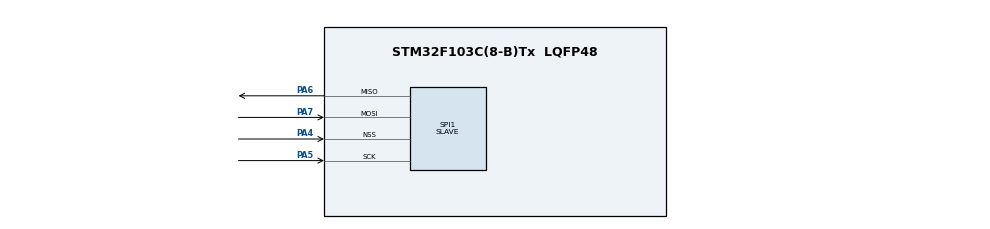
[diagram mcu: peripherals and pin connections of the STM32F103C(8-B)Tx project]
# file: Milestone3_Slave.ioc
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Mcu.Family=STM32F1
Mcu.Name=STM32F103C(8-B)Tx
Mcu.Package=LQFP48
NVIC.PriorityGroup=NVIC_PRIORITYGROUP_4
PA4.Mode=NSS_Signal_Hard_Input
PA4.Signal=SPI1_NSS
PA5.Mode=Full_Duplex_Slave
PA5.Signal=SPI1_SCK
PA6.Mode=Full_Duplex_Slave
PA6.Signal=SPI1_MISO
PA7.Mode=Full_Duplex_Slave
PA7.Signal=SPI1_MOSI
ProjectManager.HeapSize=0x200
ProjectManager.StackSize=0x400
ProjectManager.TargetToolchain=STM32CubeIDE
RCC.APB1Freq_Value=8000000
RCC.APB2Freq_Value=8000000
SPI1.Direction=SPI_DIRECTION_2LINES
SPI1.Mode=SPI_MODE_SLAVE
SPI1.VirtualNSS=VM_NSSHARD
SPI1.VirtualType=VM_SLAVE
VP_SYS_VS_ND.Mode=No_Debug
board=custom

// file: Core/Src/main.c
/* USER CODE BEGIN Header */
/**
  ******************************************************************************
  * @file           : main.c
  * @brief          : Main program body
  ******************************************************************************
  * @attention
  *
  * Copyright (c) 2026 STMicroelectronics.
  * All rights reserved.
  *
  * This software is licensed under terms that can be found in the LICENSE file
  * in the root directory of this software component.
  * If no LICENSE file comes with this software, it is provided AS-IS.
  *
  ******************************************************************************
  */
/* USER CODE END Header */
#include "main.h"

/* USER CODE BEGIN PTD */
typedef struct
{
    uint16_t id;
    uint8_t voltage_x10;
    uint16_t speed;
} CaseData;
/* USER CODE END PTD */

SPI_HandleTypeDef hspi1;

/* USER CODE BEGIN PV */
CaseData cases[5] =
{
    {0x1001, 123, 200},
    {0x1002, 142, 150},
    {0x1003, 138, 100},
    {0x1004, 115, 220},
    {0x1005, 109, 280}
};

uint8_t id_rx[2];
uint8_t tx_data[3];
/* USER CODE END PV */

void SystemClock_Config(void);
static void MX_GPIO_Init(void);
static void MX_SPI1_Init(void);

int main(void)
{

  /* MCU Configuration--------------------------------------------------------*/

  /* Reset of all peripherals, Initializes the Flash interface and the Systick. */
  HAL_Init();

  /* Configure the system clock */
  SystemClock_Config();

  /* Initialize all configured peripherals */
  MX_GPIO_Init();
  MX_SPI1_Init();

  /* Infinite loop */
  while (1)
  {
	    HAL_SPI_Receive(&hspi1,
	                    id_rx,
	                    2,
	                    HAL_MAX_DELAY);

	    uint16_t received_id =
	        ((uint16_t)id_rx[0] << 8) | id_rx[1];

	    for (int i = 0; i < 5; i++)
	    {
	        if (cases[i].id == received_id)
	        {
	            tx_data[0] = cases[i].voltage_x10;

	            tx_data[1] =
	                (cases[i].speed >> 8) & 0xFF;

	            tx_data[2] =
	                cases[i].speed & 0xFF;

	            break;
	        }
	    }

	    HAL_SPI_Transmit(&hspi1,
	                     tx_data,
	                     3,
	                     HAL_MAX_DELAY);
  }
}

void SystemClock_Config(void)
{
  RCC_OscInitTypeDef RCC_OscInitStruct = {0};
  RCC_ClkInitTypeDef RCC_ClkInitStruct = {0};

  /** Initializes the RCC Oscillators according to the specified parameters
  * in the RCC_OscInitTypeDef structure.
  */
  RCC_OscInitStruct.OscillatorType = RCC_OSCILLATORTYPE_HSI;
  RCC_OscInitStruct.HSIState = RCC_HSI_ON;
  RCC_OscInitStruct.HSICalibrationValue = RCC_HSICALIBRATION_DEFAULT;
  RCC_OscInitStruct.PLL.PLLState = RCC_PLL_NONE;
  if (HAL_RCC_OscConfig(&RCC_OscInitStruct) != HAL_OK)
  {
    Error_Handler();
  }

  /** Initializes the CPU, AHB and APB buses clocks
  */
  RCC_ClkInitStruct.ClockType = RCC_CLOCKTYPE_HCLK|RCC_CLOCKTYPE_SYSCLK
                              |RCC_CLOCKTYPE_PCLK1|RCC_CLOCKTYPE_PCLK2;
  RCC_ClkInitStruct.SYSCLKSource = RCC_SYSCLKSOURCE_HSI;
  RCC_ClkInitStruct.AHBCLKDivider = RCC_SYSCLK_DIV1;
  RCC_ClkInitStruct.APB1CLKDivider = RCC_HCLK_DIV1;
  RCC_ClkInitStruct.APB2CLKDivider = RCC_HCLK_DIV1;

  if (HAL_RCC_ClockConfig(&RCC_ClkInitStruct, FLASH_LATENCY_0) != HAL_OK)
  {
    Error_Handler();
  }
}

static void MX_SPI1_Init(void)
{

  /* SPI1 parameter configuration*/
  hspi1.Instance = SPI1;
  hspi1.Init.Mode = SPI_MODE_SLAVE;
  hspi1.Init.Direction = SPI_DIRECTION_2LINES;
  hspi1.Init.DataSize = SPI_DATASIZE_8BIT;
  hspi1.Init.CLKPolarity = SPI_POLARITY_LOW;
  hspi1.Init.CLKPhase = SPI_PHASE_1EDGE;
  hspi1.Init.NSS = SPI_NSS_HARD_INPUT;
  hspi1.Init.FirstBit = SPI_FIRSTBIT_MSB;
  hspi1.Init.TIMode = SPI_TIMODE_DISABLE;
  hspi1.Init.CRCCalculation = SPI_CRCCALCULATION_DISABLE;
  hspi1.Init.CRCPolynomial = 10;
  if (HAL_SPI_Init(&hspi1) != HAL_OK)
  {
    Error_Handler();
  }

}

static void MX_GPIO_Init(void)
{

  /* GPIO Ports Clock Enable */
  __HAL_RCC_GPIOA_CLK_ENABLE();

}

void Error_Handler(void)
{
  __disable_irq();
  while (1)
  {
  }
}
